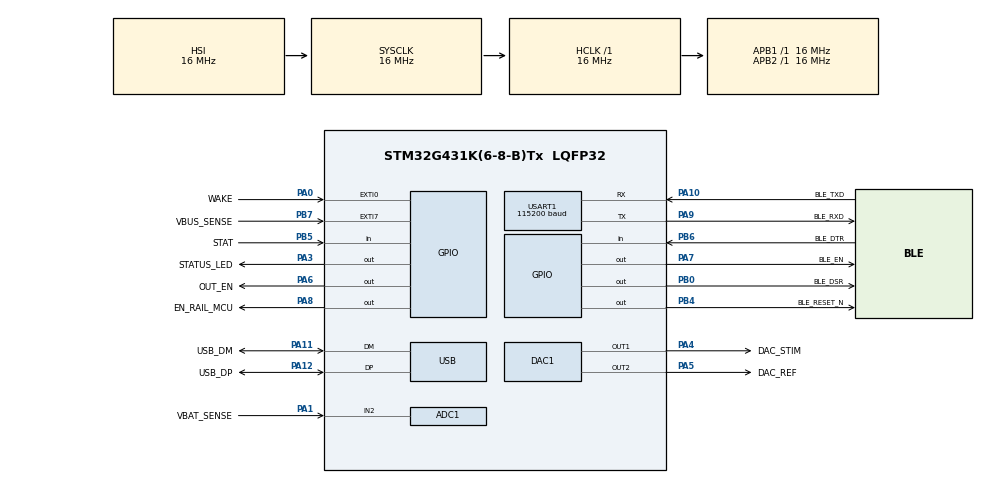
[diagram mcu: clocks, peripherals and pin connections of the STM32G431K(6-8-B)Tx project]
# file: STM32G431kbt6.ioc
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ADC1.Channel-0\#ChannelRegularConversion=ADC_CHANNEL_2
ADC1.NbrOfConversionFlag=1
ADC1.Rank-0\#ChannelRegularConversion=1
ADC1.SamplingTime-0\#ChannelRegularConversion=ADC_SAMPLETIME_640CYCLES_5
ADC1.master=1
DAC1.DAC_Channel-DAC_OUT2=DAC_CHANNEL_2
IWDG.Prescaler=IWDG_PRESCALER_32
IWDG.Reload=999
Mcu.Family=STM32G4
Mcu.Name=STM32G431K(6-8-B)Tx
Mcu.Package=LQFP32
NVIC.EXTI0_IRQn=true\:2\:0\:false\:false\:true\:true\:true\:true
NVIC.EXTI9_5_IRQn=true\:2\:0\:false\:false\:true\:true\:true\:true
NVIC.PriorityGroup=NVIC_PRIORITYGROUP_4
NVIC.TIM6_DAC_IRQn=true\:0\:0\:false\:false\:true\:true\:true\:true
NVIC.USART1_IRQn=true\:1\:0\:false\:false\:true\:true\:true\:true
PA0.GPIO_Label=WAKE
PA0.GPIO_ModeDefaultEXTI=GPIO_MODE_IT_RISING
PA0.Signal=GPXTI0
PA1.GPIO_Label=VBAT_SENSE
PA1.Mode=IN2-Single-Ended
PA1.Signal=ADC1_IN2
PA10.GPIO_Label=BLE_TXD
PA10.Mode=Asynchronous
PA10.Signal=USART1_RX
PA11.GPIO_Label=USB_DM
PA11.Mode=Device
PA11.Signal=USB_DM
PA12.GPIO_Label=USB_DP
PA12.Mode=Device
PA12.Signal=USB_DP
PA13.GPIO_Label=SWDIO
PA13.Mode=Trace_Asynchronous_SW
PA13.Signal=SYS_JTMS-SWDIO
PA14.GPIO_Label=SWCLK
PA14.Mode=Trace_Asynchronous_SW
PA14.Signal=SYS_JTCK-SWCLK
PA3.GPIO_Label=STATUS_LED
PA3.Signal=GPIO_Output
PA4.GPIO_Label=DAC_STIM
PA4.Signal=COMP_DAC11_group
PA5.GPIO_Label=DAC_REF
PA5.Signal=COMP_DAC12_group
PA6.GPIO_Label=OUT_EN
PA6.Signal=GPIO_Output
PA7.GPIO_Label=BLE_EN
PA7.Signal=GPIO_Output
PA8.GPIO_Label=EN_RAIL_MCU
PA8.Signal=GPIO_Output
PA9.GPIO_Label=BLE_RXD
PA9.Mode=Asynchronous
PA9.Signal=USART1_TX
PB0.GPIO_Label=BLE_DSR
PB0.Signal=GPIO_Output
PB3.GPIO_Label=SWO
PB3.Mode=Trace_Asynchronous_SW
PB3.Signal=SYS_JTDO-SWO
PB4.GPIO_Label=BLE_RESET_N
PB4.GPIO_ModeDefaultOutputPP=GPIO_MODE_OUTPUT_OD
PB4.Signal=GPIO_Output
PB5.GPIO_Label=STAT
PB5.Signal=GPIO_Input
PB6.GPIO_Label=BLE_DTR
PB6.GPIO_PuPd=GPIO_PULLDOWN
PB6.Signal=GPIO_Input
PB7.GPIO_Label=VBUS_SENSE
PB7.GPIO_ModeDefaultEXTI=GPIO_MODE_IT_RISING_FALLING
PB7.Signal=GPXTI7
ProjectManager.HeapSize=0x200
ProjectManager.StackSize=0x400
ProjectManager.TargetToolchain=STM32CubeIDE
RCC.AHBFreq_Value=16000000
RCC.APB1Freq_Value=16000000
RCC.APB1TimFreq_Value=16000000
RCC.APB2Freq_Value=16000000
RCC.APB2TimFreq_Value=16000000
RCC.CK48CLockSelection=RCC_USBCLKSOURCE_HSI48
RCC.CortexFreq_Value=16000000
RCC.EXTERNAL_CLOCK_VALUE=12288000
RCC.HCLKFreq_Value=16000000
RCC.HSE_VALUE=8000000
RCC.HSI48_VALUE=48000000
RCC.HSI_VALUE=16000000
RCC.LSE_VALUE=32768
RCC.SYSCLKFreq_VALUE=16000000
RCC.USBFreq_Value=48000000
RCC.VCOOutputFreq_Value=128000000
SH.COMP_DAC11_group.0=DAC1_OUT1,DAC_OUT1
SH.COMP_DAC12_group.0=DAC1_OUT2,DAC_OUT2
TIM6.AutoReloadPreload=TIM_AUTORELOAD_PRELOAD_ENABLE
TIM6.Period=249
TIM6.Prescaler=15
TIM6.TIM_MasterOutputTrigger=TIM_TRGO_UPDATE
USART1.BaudRate=115200
USART1.VirtualMode-Asynchronous=VM_ASYNC
VP_IWDG_VS_IWDG.Mode=IWDG_Activate
VP_RCC_VS_USB.Mode=USB_FS
VP_SYS_VS_DBSignals.Mode=DisableDeadBatterySignals
VP_TIM6_VS_ClockSourceINT.Mode=Enable_Timer
board=custom

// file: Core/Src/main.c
/* USER CODE BEGIN Header */
/**
  ******************************************************************************
  * @file           : main.c
  * @brief          : Main program body
  ******************************************************************************
  * @attention
  *
  * Copyright (c) 2026 STMicroelectronics.
  * All rights reserved.
  *
  * This software is licensed under terms that can be found in the LICENSE file
  * in the root directory of this software component.
  * If no LICENSE file comes with this software, it is provided AS-IS.
  *
  ******************************************************************************
  */
/* USER CODE END Header */
#include "main.h"
#include "adc.h"
#include "dac.h"
#include "iwdg.h"
#include "tim.h"
#include "usart.h"
#include "usb.h"
#include "gpio.h"

/* USER CODE BEGIN Includes */
#include "app.h"

/* USER CODE END Includes */

void SystemClock_Config(void);

int main(void)
{

  /* MCU Configuration--------------------------------------------------------*/

  /* Reset of all peripherals, Initializes the Flash interface and the Systick. */
  HAL_Init();

  /* Configure the system clock */
  SystemClock_Config();

  /* Initialize all configured peripherals */
  MX_GPIO_Init();
  MX_ADC1_Init();
  MX_DAC1_Init();
  MX_IWDG_Init();
  MX_TIM6_Init();
  MX_USART1_UART_Init();
  MX_USB_PCD_Init();
  /* USER CODE BEGIN 2 */
  app_init();

  /* USER CODE END 2 */

  /* Infinite loop */
  while (1)
  {

    /* USER CODE BEGIN 3 */
    app_poll();
    __WFI();   /* sleep until the next interrupt (SysTick wakes it every 1 ms) */
  }
  /* USER CODE END 3 */
}

void SystemClock_Config(void)
{
  RCC_OscInitTypeDef RCC_OscInitStruct = {0};
  RCC_ClkInitTypeDef RCC_ClkInitStruct = {0};
  RCC_CRSInitTypeDef pInit = {0};

  /** Configure the main internal regulator output voltage
  */
  HAL_PWREx_ControlVoltageScaling(PWR_REGULATOR_VOLTAGE_SCALE1);

  /** Initializes the RCC Oscillators according to the specified parameters
  * in the RCC_OscInitTypeDef structure.
  */
  RCC_OscInitStruct.OscillatorType = RCC_OSCILLATORTYPE_HSI|RCC_OSCILLATORTYPE_HSI48
                              |RCC_OSCILLATORTYPE_LSI;
  RCC_OscInitStruct.HSIState = RCC_HSI_ON;
  RCC_OscInitStruct.HSICalibrationValue = RCC_HSICALIBRATION_DEFAULT;
  RCC_OscInitStruct.LSIState = RCC_LSI_ON;
  RCC_OscInitStruct.HSI48State = RCC_HSI48_ON;
  RCC_OscInitStruct.PLL.PLLState = RCC_PLL_NONE;
  if (HAL_RCC_OscConfig(&RCC_OscInitStruct) != HAL_OK)
  {
    Error_Handler();
  }

  /** Initializes the CPU, AHB and APB buses clocks
  */
  RCC_ClkInitStruct.ClockType = RCC_CLOCKTYPE_HCLK|RCC_CLOCKTYPE_SYSCLK
                              |RCC_CLOCKTYPE_PCLK1|RCC_CLOCKTYPE_PCLK2;
  RCC_ClkInitStruct.SYSCLKSource = RCC_SYSCLKSOURCE_HSI;
  RCC_ClkInitStruct.AHBCLKDivider = RCC_SYSCLK_DIV1;
  RCC_ClkInitStruct.APB1CLKDivider = RCC_HCLK_DIV1;
  RCC_ClkInitStruct.APB2CLKDivider = RCC_HCLK_DIV1;

  if (HAL_RCC_ClockConfig(&RCC_ClkInitStruct, FLASH_LATENCY_0) != HAL_OK)
  {
    Error_Handler();
  }

  /** Enable the SYSCFG APB clock
  */
  __HAL_RCC_CRS_CLK_ENABLE();

  /** Configures CRS
  */
  pInit.Prescaler = RCC_CRS_SYNC_DIV1;
  pInit.Source = RCC_CRS_SYNC_SOURCE_USB;
  pInit.Polarity = RCC_CRS_SYNC_POLARITY_RISING;
  pInit.ReloadValue = __HAL_RCC_CRS_RELOADVALUE_CALCULATE(48000000,1000);
  pInit.ErrorLimitValue = 34;
  pInit.HSI48CalibrationValue = 32;

  HAL_RCCEx_CRSConfig(&pInit);
}

void Error_Handler(void)
{
  __disable_irq();
  while (1)
  {
  }
}
